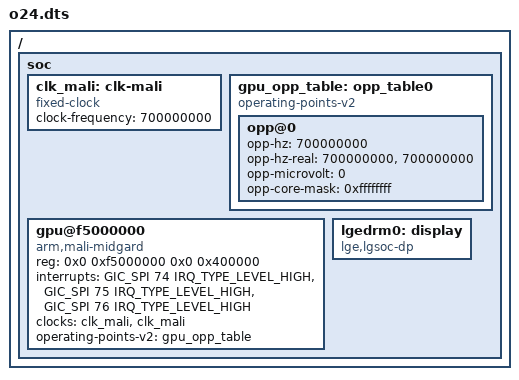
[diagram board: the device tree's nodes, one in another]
#include "../lg1214-o24-psci.dts"

/ {
	soc {

		clk_mali: clk-mali {
			compatible = "fixed-clock";
			clock-frequency = <700000000>;

			#clock-cells = <0>;
		};
		gpu_opp_table: opp_table0 {
			compatible = "operating-points-v2", "operating-points-v2-mali";
			opp@0 {
				opp-hz = /bits/ 64 <700000000>;
				opp-hz-real = /bits/ 64 <700000000>, /bits/ 64 <700000000>;
				opp-microvolt = <0>;
				opp-core-mask = /bits/ 64 <0xffffffff>;
			};
		};
		gpu@f5000000 {
			compatible = "arm,mali-midgard";
			reg = <0x0 0xf5000000 0x0 0x400000>;
			interrupts = <GIC_SPI 74 IRQ_TYPE_LEVEL_HIGH>,
			             <GIC_SPI 75 IRQ_TYPE_LEVEL_HIGH>,
			             <GIC_SPI 76 IRQ_TYPE_LEVEL_HIGH>;
			interrupt-names = "JOB", "MMU", "GPU";

			clocks = <&clk_mali>, <&clk_mali>;
			clock-names = "clk_mali", "shadercores";

			operating-points-v2 = <&gpu_opp_table>;
		};

		lgedrm0: display {
			compatible = "lge,lgsoc-dp";
		};
	};
};
